VERSION ""

NS_ :

BS_:

BU_: Tester ECU
VAL_TABLE_ CanNmPnFilterMaskByte_1 32 "ComMUser_PN29" ;
VAL_TABLE_ CanNmPnFilterMaskByte_0 2 "ComMUser_PN17" ;
VAL_TABLE_ TemperatureSensor 255 "SNA" ;

BO_ 624 CAN0_Rx_0x270_TSyn_Slave: 8 Tester
 SG_ CAN_TSyn_Rx : 7|64@0+ (1,0) [0|1.84467440737096E+019] ""  ECU

BO_ 880 CAN0_Tx_0x370_TSyn_Master: 8 ECU
 SG_ CAN_TSyn_Tx : 7|64@0+ (1,0) [0|1.84467440737096E+019] ""  Tester

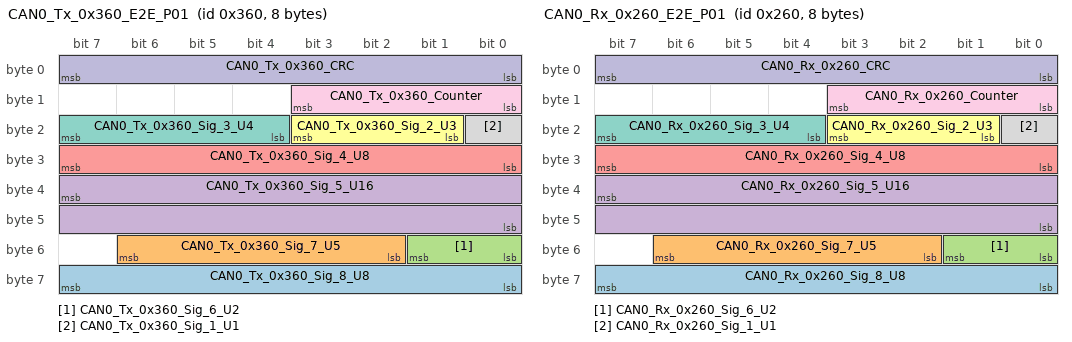
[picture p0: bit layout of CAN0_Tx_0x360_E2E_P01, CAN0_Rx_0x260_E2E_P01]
BO_ 864 CAN0_Tx_0x360_E2E_P01: 8 ECU
 SG_ CAN0_Tx_0x360_Sig_8_U8 : 63|8@0+ (1,0) [0|255] ""  Tester
 SG_ CAN0_Tx_0x360_Sig_7_U5 : 54|5@0+ (1,0) [0|31] ""  Tester
 SG_ CAN0_Tx_0x360_Sig_6_U2 : 49|2@0+ (1,0) [0|3] ""  Tester
 SG_ CAN0_Tx_0x360_Sig_5_U16 : 39|16@0+ (1,0) [0|65535] ""  Tester
 SG_ CAN0_Tx_0x360_Sig_4_U8 : 31|8@0+ (1,0) [0|255] ""  Tester
 SG_ CAN0_Tx_0x360_Sig_2_U3 : 19|3@0+ (1,0) [0|7] ""  Tester
 SG_ CAN0_Tx_0x360_Sig_3_U4 : 23|4@0+ (1,0) [0|15] ""  Tester
 SG_ CAN0_Tx_0x360_Sig_1_U1 : 16|1@0+ (1,0) [0|1] ""  Tester
 SG_ CAN0_Tx_0x360_Counter : 11|4@0+ (1,0) [0|15] ""  Tester
 SG_ CAN0_Tx_0x360_CRC : 7|8@0+ (1,0) [0|255] ""  Tester

BO_ 608 CAN0_Rx_0x260_E2E_P01: 8 Tester
 SG_ CAN0_Rx_0x260_Sig_8_U8 : 63|8@0+ (1,0) [0|255] ""  ECU
 SG_ CAN0_Rx_0x260_Sig_7_U5 : 54|5@0+ (1,0) [0|31] ""  ECU
 SG_ CAN0_Rx_0x260_Sig_6_U2 : 49|2@0+ (1,0) [0|3] ""  ECU
 SG_ CAN0_Rx_0x260_Sig_5_U16 : 39|16@0+ (1,0) [0|65535] ""  ECU
 SG_ CAN0_Rx_0x260_Sig_4_U8 : 31|8@0+ (1,0) [0|255] ""  ECU
 SG_ CAN0_Rx_0x260_Sig_2_U3 : 19|3@0+ (1,0) [0|7] ""  ECU
 SG_ CAN0_Rx_0x260_Sig_3_U4 : 23|4@0+ (1,0) [0|15] ""  ECU
 SG_ CAN0_Rx_0x260_Sig_1_U1 : 16|1@0+ (1,0) [0|1] ""  ECU
 SG_ CAN0_Rx_0x260_Counter : 11|4@0+ (1,0) [0|15] ""  ECU
 SG_ CAN0_Rx_0x260_CRC : 7|8@0+ (1,0) [0|255] ""  ECU

BO_ 593 CAN0_Rx_0x251_Cyclic_PN29: 8 Tester
 SG_ CAN0_Rx_0x251_Cyclic_PN29_Sig : 7|16@0+ (1,0) [0|65535] ""  ECU

BO_ 849 CAN0_Tx_0x351_Cyclic_PN29: 8 ECU
 SG_ CAN0_Tx_0x351_Cyclic_PN29_Sig : 7|16@0+ (1,0) [0|65535] ""  Tester

BO_ 592 CAN0_Rx_0x250_Cyclic_PN17: 8 Tester
 SG_ CAN0_Rx_0x250_Cyclic_PN17_Sig : 7|16@0+ (1,0) [0|65535] ""  ECU

BO_ 848 CAN0_Tx_0x350_Cyclic_PN17: 8 ECU
 SG_ CAN0_Tx_0x350_Cyclic_PN17_Sig : 7|16@0+ (1,0) [0|65535] ""  Tester

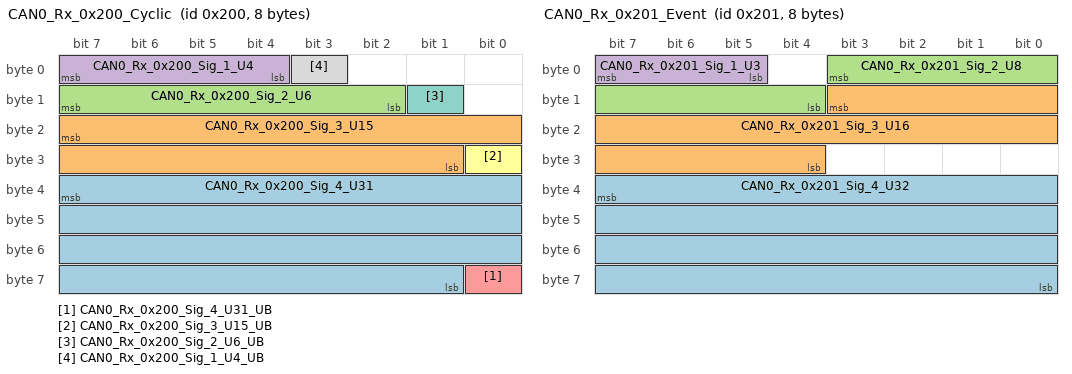
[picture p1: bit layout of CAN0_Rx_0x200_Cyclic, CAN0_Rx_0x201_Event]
BO_ 512 CAN0_Rx_0x200_Cyclic: 8 Tester
 SG_ CAN0_Rx_0x200_Sig_4_U31 : 39|31@0+ (1,0) [0|0] ""  ECU
 SG_ CAN0_Rx_0x200_Sig_3_U15 : 23|15@0+ (1,0) [0|0] ""  ECU
 SG_ CAN0_Rx_0x200_Sig_2_U6 : 15|6@0+ (1,0) [0|0] ""  ECU
 SG_ CAN0_Rx_0x200_Sig_1_U4 : 7|4@0+ (1,0) [0|15] ""  ECU
 SG_ CAN0_Rx_0x200_Sig_4_U31_UB : 56|1@0+ (1,0) [0|0] ""  ECU
 SG_ CAN0_Rx_0x200_Sig_3_U15_UB : 24|1@0+ (1,0) [0|0] ""  ECU
 SG_ CAN0_Rx_0x200_Sig_2_U6_UB : 9|1@0+ (1,0) [0|0] ""  ECU
 SG_ CAN0_Rx_0x200_Sig_1_U4_UB : 3|1@0+ (1,0) [0|15] ""  ECU

BO_ 513 CAN0_Rx_0x201_Event: 8 Tester
 SG_ CAN0_Rx_0x201_Sig_4_U32 : 39|32@0+ (1,0) [0|0] ""  ECU
 SG_ CAN0_Rx_0x201_Sig_3_U16 : 11|16@0+ (1,0) [0|0] ""  ECU
 SG_ CAN0_Rx_0x201_Sig_2_U8 : 3|8@0+ (1,0) [0|0] ""  ECU
 SG_ CAN0_Rx_0x201_Sig_1_U3 : 7|3@0+ (1,0) [0|15] ""  ECU

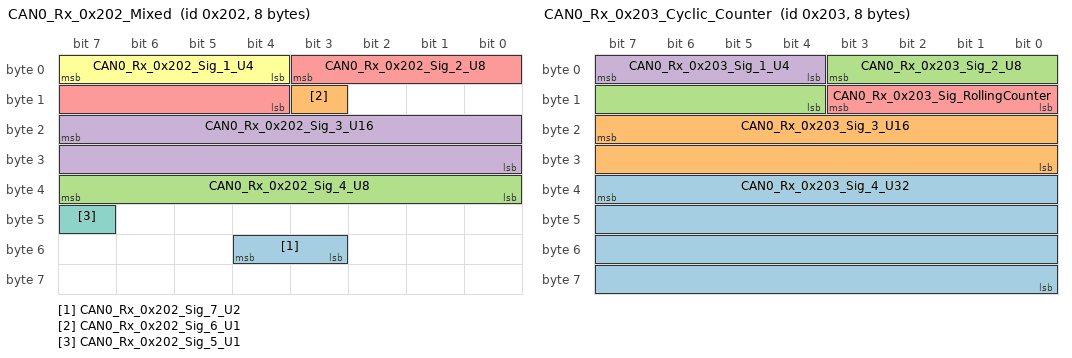
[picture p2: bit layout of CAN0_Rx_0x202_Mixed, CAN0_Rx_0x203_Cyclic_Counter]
BO_ 514 CAN0_Rx_0x202_Mixed: 8 Tester
 SG_ CAN0_Rx_0x202_Sig_7_U2 : 52|2@0+ (1,0) [0|15] ""  ECU
 SG_ CAN0_Rx_0x202_Sig_6_U1 : 11|1@0+ (1,0) [0|15] ""  ECU
 SG_ CAN0_Rx_0x202_Sig_4_U8 : 39|8@0+ (1,0) [0|0] ""  ECU
 SG_ CAN0_Rx_0x202_Sig_3_U16 : 23|16@0+ (1,0) [0|0] ""  ECU
 SG_ CAN0_Rx_0x202_Sig_2_U8 : 3|8@0+ (1,0) [0|0] ""  ECU
 SG_ CAN0_Rx_0x202_Sig_1_U4 : 7|4@0+ (1,0) [0|15] ""  ECU
 SG_ CAN0_Rx_0x202_Sig_5_U1 : 47|1@0+ (1,0) [0|15] ""  ECU

BO_ 515 CAN0_Rx_0x203_Cyclic_Counter: 8 Tester
 SG_ CAN0_Rx_0x203_Sig_4_U32 : 39|32@0+ (1,0) [0|0] ""  ECU
 SG_ CAN0_Rx_0x203_Sig_3_U16 : 23|16@0+ (1,0) [0|0] ""  ECU
 SG_ CAN0_Rx_0x203_Sig_2_U8 : 3|8@0+ (1,0) [0|0] ""  ECU
 SG_ CAN0_Rx_0x203_Sig_1_U4 : 7|4@0+ (1,0) [0|15] ""  ECU
 SG_ CAN0_Rx_0x203_Sig_RollingCounter : 11|4@0+ (1,0) [0|15] ""  ECU

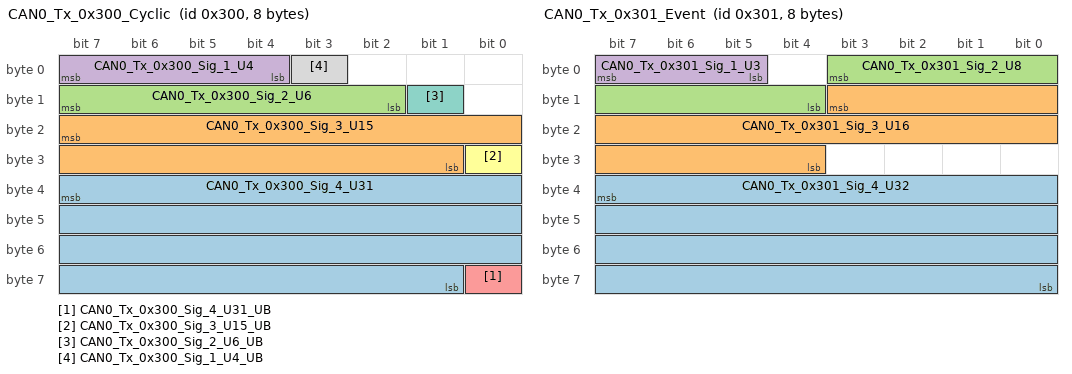
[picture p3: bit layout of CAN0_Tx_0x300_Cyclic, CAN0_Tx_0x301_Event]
BO_ 768 CAN0_Tx_0x300_Cyclic: 8 ECU
 SG_ CAN0_Tx_0x300_Sig_4_U31 : 39|31@0+ (1,0) [0|0] ""  Tester
 SG_ CAN0_Tx_0x300_Sig_3_U15 : 23|15@0+ (1,0) [0|0] ""  Tester
 SG_ CAN0_Tx_0x300_Sig_2_U6 : 15|6@0+ (1,0) [0|0] ""  Tester
 SG_ CAN0_Tx_0x300_Sig_1_U4 : 7|4@0+ (1,0) [0|15] ""  Tester
 SG_ CAN0_Tx_0x300_Sig_4_U31_UB : 56|1@0+ (1,0) [0|0] ""  Tester
 SG_ CAN0_Tx_0x300_Sig_3_U15_UB : 24|1@0+ (1,0) [0|0] ""  Tester
 SG_ CAN0_Tx_0x300_Sig_2_U6_UB : 9|1@0+ (1,0) [0|0] ""  Tester
 SG_ CAN0_Tx_0x300_Sig_1_U4_UB : 3|1@0+ (1,0) [0|15] ""  Tester

BO_ 769 CAN0_Tx_0x301_Event: 8 ECU
 SG_ CAN0_Tx_0x301_Sig_4_U32 : 39|32@0+ (1,0) [0|0] ""  Tester
 SG_ CAN0_Tx_0x301_Sig_3_U16 : 11|16@0+ (1,0) [0|0] ""  Tester
 SG_ CAN0_Tx_0x301_Sig_2_U8 : 3|8@0+ (1,0) [0|0] ""  Tester
 SG_ CAN0_Tx_0x301_Sig_1_U3 : 7|3@0+ (1,0) [0|15] ""  Tester

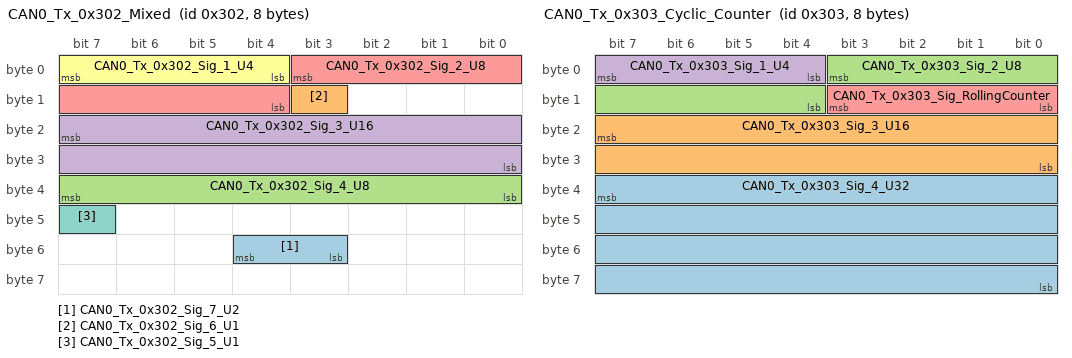
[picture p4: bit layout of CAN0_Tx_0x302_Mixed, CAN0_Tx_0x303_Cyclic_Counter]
BO_ 770 CAN0_Tx_0x302_Mixed: 8 ECU
 SG_ CAN0_Tx_0x302_Sig_7_U2 : 52|2@0+ (1,0) [0|15] ""  Tester
 SG_ CAN0_Tx_0x302_Sig_6_U1 : 11|1@0+ (1,0) [0|15] ""  Tester
 SG_ CAN0_Tx_0x302_Sig_4_U8 : 39|8@0+ (1,0) [0|0] ""  Tester
 SG_ CAN0_Tx_0x302_Sig_3_U16 : 23|16@0+ (1,0) [0|0] ""  Tester
 SG_ CAN0_Tx_0x302_Sig_2_U8 : 3|8@0+ (1,0) [0|0] ""  Tester
 SG_ CAN0_Tx_0x302_Sig_1_U4 : 7|4@0+ (1,0) [0|15] ""  Tester
 SG_ CAN0_Tx_0x302_Sig_5_U1 : 47|1@0+ (1,0) [0|15] ""  Tester

BO_ 771 CAN0_Tx_0x303_Cyclic_Counter: 8 ECU
 SG_ CAN0_Tx_0x303_Sig_4_U32 : 39|32@0+ (1,0) [0|0] ""  Tester
 SG_ CAN0_Tx_0x303_Sig_3_U16 : 23|16@0+ (1,0) [0|0] ""  Tester
 SG_ CAN0_Tx_0x303_Sig_2_U8 : 3|8@0+ (1,0) [0|0] ""  Tester
 SG_ CAN0_Tx_0x303_Sig_1_U4 : 7|4@0+ (1,0) [0|15] ""  Tester
 SG_ CAN0_Tx_0x303_Sig_RollingCounter : 11|4@0+ (1,0) [0|15] ""  Tester

BO_ 1551 CAN0_Tx_0x60F_XCP_Slave: 8 ECU
 SG_ XCP_Slave : 7|64@0+ (1,0) [0|1.84467440737096E+019] ""  Tester

BO_ 1537 CAN0_Rx_0x601_XCP_Master: 8 Tester
 SG_ XCP_Master : 7|64@0+ (1,0) [0|1.84467440737096E+019] ""  ECU

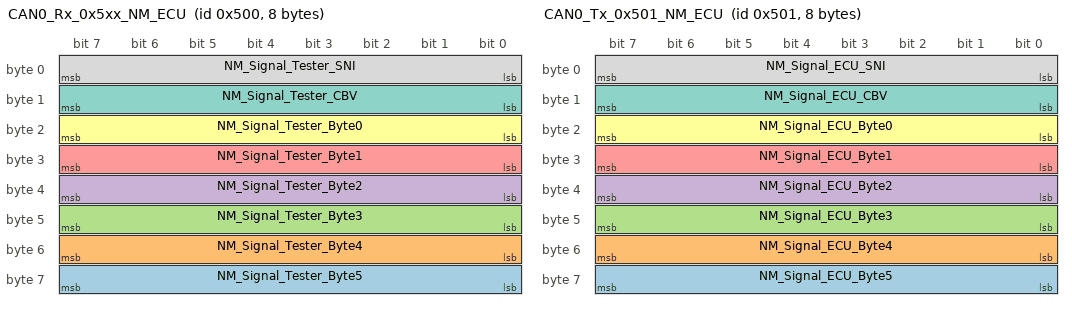
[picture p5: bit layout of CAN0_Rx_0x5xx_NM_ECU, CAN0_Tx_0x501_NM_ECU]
BO_ 1280 CAN0_Rx_0x5xx_NM_ECU: 8 Tester
 SG_ NM_Signal_Tester_Byte5 : 63|8@0+ (1,0) [0|255] ""  ECU
 SG_ NM_Signal_Tester_Byte4 : 55|8@0+ (1,0) [0|255] ""  ECU
 SG_ NM_Signal_Tester_Byte3 : 47|8@0+ (1,0) [0|255] ""  ECU
 SG_ NM_Signal_Tester_Byte2 : 39|8@0+ (1,0) [0|255] ""  ECU
 SG_ NM_Signal_Tester_Byte1 : 31|8@0+ (1,0) [0|255] ""  ECU
 SG_ NM_Signal_Tester_Byte0 : 23|8@0+ (1,0) [0|255] ""  ECU
 SG_ NM_Signal_Tester_CBV : 15|8@0+ (1,0) [0|255] ""  ECU
 SG_ NM_Signal_Tester_SNI : 7|8@0+ (1,0) [0|255] ""  ECU

BO_ 1801 CAN0_Tx_0x709_Diag_Phy_Response: 8 ECU
 SG_ Diag_Phy_Response : 7|64@0+ (1,0) [0|0] ""  Tester

BO_ 1281 CAN0_Tx_0x501_NM_ECU: 8 ECU
 SG_ NM_Signal_ECU_Byte5 : 63|8@0+ (1,0) [0|255] ""  Tester
 SG_ NM_Signal_ECU_Byte4 : 55|8@0+ (1,0) [0|255] ""  Tester
 SG_ NM_Signal_ECU_Byte3 : 47|8@0+ (1,0) [0|255] ""  Tester
 SG_ NM_Signal_ECU_Byte2 : 39|8@0+ (1,0) [0|255] ""  Tester
 SG_ NM_Signal_ECU_Byte1 : 31|8@0+ (1,0) [0|255] ""  Tester
 SG_ NM_Signal_ECU_Byte0 : 23|8@0+ (1,0) [0|255] ""  Tester
 SG_ NM_Signal_ECU_CBV : 15|8@0+ (1,0) [0|255] ""  Tester
 SG_ NM_Signal_ECU_SNI : 7|8@0+ (1,0) [0|255] ""  Tester

BO_ 2015 CAN0_Rx_0x7df_Diag_Fun_Request: 8 Tester
 SG_ Diag_Fun_Request : 7|64@0+ (1,0) [0|1.84467440737096E+019] ""  ECU

BO_ 1800 CAN0_Rx_0x708_Diag_Phy_Request: 8 Tester
 SG_ Diag_Phy_Request : 7|64@0+ (1,0) [0|1.84467440737096E+019] ""  ECU

CM_ BO_ 864 "DATAID��0x1234";
CM_ BO_ 608 "DATAID��0x1234";
BA_DEF_ SG_  "GenSigTimeoutTime" INT 0 65535;
BA_DEF_ SG_  "GenSigSendType" ENUM  "Cyclic","OnWrite","OnWriteWithRepetition","OnChange","OnChangeWithRepetition","NotUsed","NotUsed","NoSigSendType";
BA_DEF_  "NmType" STRING ;
BA_DEF_ BO_  "NmMessage" ENUM  "No","Yes";
BA_DEF_  "NmAsrWaitBusSleepTime" INT 0 65535;
BA_DEF_  "NmAsrTimeoutTime" INT 1 65535;
BA_DEF_  "NmAsrRepeatMessageTime" INT 0 65535;
BA_DEF_ BU_  "NMAsrNodeIdentifier" HEX 0 255;
BA_DEF_ BU_  "NmAsrNode" ENUM  "No","Yes";
BA_DEF_  "NmAsrMessageCount" INT 1 256;
BA_DEF_ BO_  "NmAsrMessage" ENUM  "No","Yes";
BA_DEF_ BU_  "NmAsrCanMsgReducedTime" INT 0 65535;
BA_DEF_  "NmAsrCanMsgCycleTime" INT 1 65535;
BA_DEF_  "NmAsrBaseAddress" HEX 0 2047;
BA_DEF_ BU_  "ILUsed" ENUM  "No","Yes";
BA_DEF_ SG_  "GenSigValidAfterKL15" ENUM  "Y","N","Null";
BA_DEF_ SG_  "GenSigStartValue" INT 0 2147483647;
BA_DEF_ SG_  "GenSigInactiveValue" INT 0 2147483647;
BA_DEF_ SG_  "GenSigGWTimeoutValue" HEX 0 300000;
BA_DEF_ BO_  "GenMsgILSupport" ENUM  "No","Yes";
BA_DEF_ BO_  "GenMsgDelayTime" INT 0 1000;
BA_DEF_ BO_  "GenMsgCycleTimeFast" INT 0 300000;
BA_DEF_ BO_  "GenMsgCycleTime" INT 0 300000;
BA_DEF_ BO_  "DiagState" ENUM  "No","Yes";
BA_DEF_ BO_  "DiagResponse" ENUM  "No","Yes";
BA_DEF_ BO_  "DiagRequest" ENUM  "No","Yes";
BA_DEF_ BO_  "GenMsgNrOfRepetition" INT 0 0;
BA_DEF_ BO_  "GenMsgSendType" ENUM  "Cyclic","Event","Mixed";
BA_DEF_ BO_  "CANFD_BRS" ENUM  "0","1";
BA_DEF_  "DBName" STRING ;
BA_DEF_  "BusType" STRING ;
BA_DEF_ BO_  "VFrameFormat" ENUM  "StandardCAN","ExtendedCAN","reserved","reserved","reserved","reserved","reserved","reserved","reserved","reserved","reserved","reserved","reserved","reserved","StandardCAN_FD","ExtendedCAN_FD";
BA_DEF_DEF_  "GenSigTimeoutTime" 0;
BA_DEF_DEF_  "GenSigSendType" "Cyclic";
BA_DEF_DEF_  "NmType" "NmAsr";
BA_DEF_DEF_  "NmMessage" "No";
BA_DEF_DEF_  "NmAsrWaitBusSleepTime" 1500;
BA_DEF_DEF_  "NmAsrTimeoutTime" 5000;
BA_DEF_DEF_  "NmAsrRepeatMessageTime" 500;
BA_DEF_DEF_  "NMAsrNodeIdentifier" 0;
BA_DEF_DEF_  "NmAsrNode" "No";
BA_DEF_DEF_  "NmAsrMessageCount" 128;
BA_DEF_DEF_  "NmAsrMessage" "No";
BA_DEF_DEF_  "NmAsrCanMsgReducedTime" 100;
BA_DEF_DEF_  "NmAsrCanMsgCycleTime" 200;
BA_DEF_DEF_  "NmAsrBaseAddress" 1280;
BA_DEF_DEF_  "ILUsed" "Yes";
BA_DEF_DEF_  "GenSigValidAfterKL15" "Y";
BA_DEF_DEF_  "GenSigStartValue" 0;
BA_DEF_DEF_  "GenSigInactiveValue" 0;
BA_DEF_DEF_  "GenSigGWTimeoutValue" 0;
BA_DEF_DEF_  "GenMsgILSupport" "Yes";
BA_DEF_DEF_  "GenMsgDelayTime" 0;
BA_DEF_DEF_  "GenMsgCycleTimeFast" 0;
BA_DEF_DEF_  "GenMsgCycleTime" 0;
BA_DEF_DEF_  "DiagState" "No";
BA_DEF_DEF_  "DiagResponse" "No";
BA_DEF_DEF_  "DiagRequest" "No";
BA_DEF_DEF_  "GenMsgNrOfRepetition" 0;
BA_DEF_DEF_  "GenMsgSendType" "Cyclic";
BA_DEF_DEF_  "CANFD_BRS" "1";
BA_DEF_DEF_  "DBName" "";
BA_DEF_DEF_  "BusType" "";
BA_DEF_DEF_  "VFrameFormat" "StandardCAN";
BA_ "BusType" "CAN";
BA_ "NmAsrTimeoutTime" 3000;
BA_ "NmAsrRepeatMessageTime" 3000;
BA_ "NmAsrMessageCount" 256;
BA_ "NmAsrCanMsgCycleTime" 1000;
BA_ "DBName" "CAN_Demo";
BA_ "NmAsrNode" BU_ Tester 1;
BA_ "NmAsrCanMsgReducedTime" BU_ Tester 600;
BA_ "NmAsrNode" BU_ ECU 1;
BA_ "NMAsrNodeIdentifier" BU_ ECU 1;
BA_ "NmAsrCanMsgReducedTime" BU_ ECU 500;
BA_ "GenMsgILSupport" BO_ 624 0;
BA_ "GenMsgCycleTime" BO_ 624 100;
BA_ "GenMsgILSupport" BO_ 880 0;
BA_ "GenMsgCycleTime" BO_ 880 100;
BA_ "GenMsgCycleTime" BO_ 864 100;
BA_ "GenMsgCycleTime" BO_ 608 100;
BA_ "GenMsgCycleTime" BO_ 593 100;
BA_ "GenMsgCycleTime" BO_ 849 100;
BA_ "GenMsgCycleTime" BO_ 592 100;
BA_ "GenMsgCycleTime" BO_ 848 100;
BA_ "GenMsgCycleTime" BO_ 512 100;
BA_ "GenMsgSendType" BO_ 513 1;
BA_ "GenMsgNrOfRepetition" BO_ 513 3;
BA_ "GenMsgCycleTime" BO_ 514 500;
BA_ "GenMsgCycleTimeFast" BO_ 514 50;
BA_ "GenMsgSendType" BO_ 514 2;
BA_ "GenMsgCycleTime" BO_ 515 50;
BA_ "GenMsgCycleTime" BO_ 768 100;
BA_ "GenMsgSendType" BO_ 769 1;
BA_ "GenMsgNrOfRepetition" BO_ 769 3;
BA_ "GenMsgCycleTimeFast" BO_ 769 50;
BA_ "GenMsgDelayTime" BO_ 769 10;
BA_ "GenMsgSendType" BO_ 770 2;
BA_ "GenMsgNrOfRepetition" BO_ 770 3;
BA_ "GenMsgCycleTimeFast" BO_ 770 50;
BA_ "GenMsgCycleTime" BO_ 770 500;
BA_ "GenMsgDelayTime" BO_ 770 10;
BA_ "GenMsgCycleTime" BO_ 771 50;
BA_ "GenMsgILSupport" BO_ 1551 0;
BA_ "GenMsgSendType" BO_ 1551 1;
BA_ "GenMsgILSupport" BO_ 1537 0;
BA_ "GenMsgSendType" BO_ 1537 1;
BA_ "NmMessage" BO_ 1280 1;
BA_ "NmAsrMessage" BO_ 1280 1;
BA_ "GenMsgILSupport" BO_ 1280 0;
BA_ "DiagResponse" BO_ 1801 1;
BA_ "GenMsgILSupport" BO_ 1801 0;
BA_ "GenMsgSendType" BO_ 1801 1;
BA_ "NmMessage" BO_ 1281 1;
BA_ "NmAsrMessage" BO_ 1281 1;
BA_ "GenMsgILSupport" BO_ 1281 0;
BA_ "DiagState" BO_ 2015 1;
BA_ "GenMsgILSupport" BO_ 2015 0;
BA_ "GenMsgSendType" BO_ 2015 1;
BA_ "DiagRequest" BO_ 1800 1;
BA_ "GenMsgILSupport" BO_ 1800 0;
BA_ "GenMsgSendType" BO_ 1800 1;
BA_ "GenSigSendType" SG_ 512 CAN0_Rx_0x200_Sig_4_U31_UB 7;
BA_ "GenSigSendType" SG_ 512 CAN0_Rx_0x200_Sig_3_U15_UB 7;
BA_ "GenSigSendType" SG_ 512 CAN0_Rx_0x200_Sig_2_U6_UB 7;
BA_ "GenSigSendType" SG_ 512 CAN0_Rx_0x200_Sig_1_U4_UB 7;
BA_ "GenSigInactiveValue" SG_ 513 CAN0_Rx_0x201_Sig_2_U8 255;
BA_ "GenSigTimeoutTime" SG_ 514 CAN0_Rx_0x202_Sig_7_U2 2500;
BA_ "GenSigSendType" SG_ 768 CAN0_Tx_0x300_Sig_4_U31_UB 7;
BA_ "GenSigSendType" SG_ 768 CAN0_Tx_0x300_Sig_3_U15_UB 7;
BA_ "GenSigSendType" SG_ 768 CAN0_Tx_0x300_Sig_2_U6_UB 7;
BA_ "GenSigSendType" SG_ 768 CAN0_Tx_0x300_Sig_1_U4_UB 7;
BA_ "GenSigSendType" SG_ 769 CAN0_Tx_0x301_Sig_4_U32 1;
BA_ "GenSigSendType" SG_ 769 CAN0_Tx_0x301_Sig_3_U16 1;
BA_ "GenSigSendType" SG_ 769 CAN0_Tx_0x301_Sig_2_U8 1;
BA_ "GenSigSendType" SG_ 769 CAN0_Tx_0x301_Sig_1_U3 1;
BA_ "GenSigSendType" SG_ 770 CAN0_Tx_0x302_Sig_7_U2 2;
BA_ "GenSigSendType" SG_ 770 CAN0_Tx_0x302_Sig_6_U1 2;
BA_ "GenSigSendType" SG_ 770 CAN0_Tx_0x302_Sig_4_U8 2;
BA_ "GenSigSendType" SG_ 770 CAN0_Tx_0x302_Sig_3_U16 2;
BA_ "GenSigSendType" SG_ 770 CAN0_Tx_0x302_Sig_2_U8 2;
BA_ "GenSigSendType" SG_ 770 CAN0_Tx_0x302_Sig_1_U4 2;
BA_ "GenSigSendType" SG_ 770 CAN0_Tx_0x302_Sig_5_U1 2;
BA_ "GenSigValidAfterKL15" SG_ 1551 XCP_Slave 2;
BA_ "GenSigValidAfterKL15" SG_ 1537 XCP_Master 2;
VAL_ 513 CAN0_Rx_0x201_Sig_2_U8 255 "SNA" ;
VAL_ 1280 NM_Signal_Tester_Byte1 32 "ComMUser_PN29" ;
VAL_ 1280 NM_Signal_Tester_Byte0 2 "ComMUser_PN17" ;
VAL_ 1281 NM_Signal_ECU_Byte1 32 "ComMUser_PN29" ;
VAL_ 1281 NM_Signal_ECU_Byte0 2 "ComMUser_PN17" ;
SIG_GROUP_ 864 Tx_0x360_E2E_P01 1 : CAN0_Tx_0x360_Sig_8_U8 CAN0_Tx_0x360_Sig_7_U5;
SIG_GROUP_ 608 Rx_0x260_E2E_P01 1 : CAN0_Rx_0x260_Sig_8_U8 CAN0_Rx_0x260_Sig_7_U5 CAN0_Rx_0x260_Sig_6_U2 CAN0_Rx_0x260_Sig_5_U16 CAN0_Rx_0x260_Sig_4_U8 CAN0_Rx_0x260_Sig_3_U4 CAN0_Rx_0x260_Sig_2_U3 CAN0_Rx_0x260_Sig_1_U1 CAN0_Rx_0x260_Counter CAN0_Rx_0x260_CRC;
